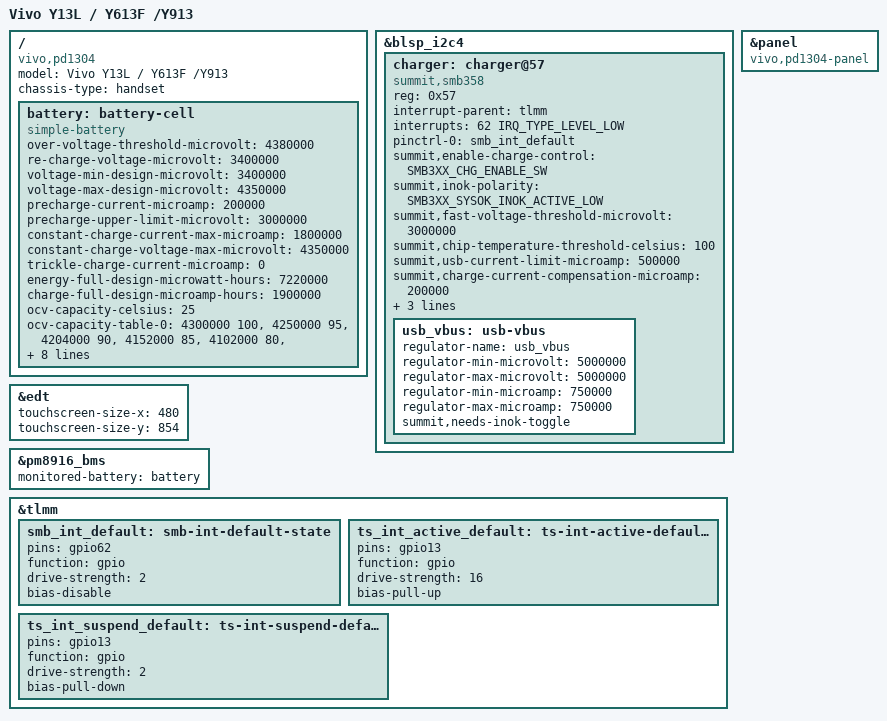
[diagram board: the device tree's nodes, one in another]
// SPDX-License-Identifier: GPL-2.0-only

/dts-v1/;

#include "msm8916-vivo-cdp.dtsi"



/ {
	model = "Vivo Y13L / Y613F /Y913";
	compatible = "vivo,pd1304", "qcom,msm8916";
	chassis-type = "handset";
	
	battery: battery-cell {
		compatible = "simple-battery";
		over-voltage-threshold-microvolt = <4380000>;
		re-charge-voltage-microvolt = <3400000>;
		voltage-min-design-microvolt = <3400000>;
		voltage-max-design-microvolt = <4350000>;

		precharge-current-microamp = <200000>;
		precharge-upper-limit-microvolt = <3000000>;
		constant-charge-current-max-microamp = <1800000>;
		constant-charge-voltage-max-microvolt = <4350000>;
		trickle-charge-current-microamp = <0>;

		energy-full-design-microwatt-hours = <7220000>;
		charge-full-design-microamp-hours = <1900000>;

		ocv-capacity-celsius = <25>;
		ocv-capacity-table-0 = <4300000 100>, <4250000 95>, <4204000 90>,
			<4152000 85>, <4102000 80>, <4060000 75>, <3998000 70>,
			<3964000 65>, <3924000 60>, <3874000 55>, <3842000 50>,
			<3820000 45>, <3800000 40>, <3785000 35>, <3765000 30>,
			<3758000 25>, <3735000 20>, <3706000 16>, <3690000 13>,
			<3687000 11>, <3686000 10>, <3684000 9>, <3680000 8>,
			<3668000 7>, <3640000 6>, <3596000 5>, <3542000 4>,
			<3472000 3>, <3378000 2>, <3239000 1>, <3000000 0>;
	};
	

};

&blsp_i2c4 {
	status = "okay";

	charger: charger@57 {
		compatible = "summit,smb358";
		reg = <0x57>;

		interrupt-parent = <&tlmm>;
		interrupts = <62 IRQ_TYPE_LEVEL_LOW>;

		pinctrl-names = "default";
		pinctrl-0 = <&smb_int_default>;

		summit,enable-charge-control = <SMB3XX_CHG_ENABLE_SW>;
		summit,inok-polarity = <SMB3XX_SYSOK_INOK_ACTIVE_LOW>;
		summit,fast-voltage-threshold-microvolt = <3000000>;
		summit,chip-temperature-threshold-celsius = <100>;
		summit,usb-current-limit-microamp = <500000>;
		summit,charge-current-compensation-microamp = <200000>;
		summit,enable-usb-charging;
		summit,enable-otg-charging;

		monitored-battery = <&battery>;

		usb_vbus: usb-vbus {
			regulator-name = "usb_vbus";
			regulator-min-microvolt = <5000000>;
			regulator-max-microvolt = <5000000>;
			regulator-min-microamp = <750000>;
			regulator-max-microamp = <750000>;
			summit,needs-inok-toggle;
		};
	};
};

&edt{
	touchscreen-size-x = <480>;
	touchscreen-size-y = <854>;

};

&pm8916_bms {
	monitored-battery = <&battery>;
	status = "okay";
};


&panel {
    compatible = "vivo,pd1304-panel"; 


};

&tlmm{

    smb_int_default: smb-int-default-state {
		pins = "gpio62";
		function = "gpio";

		drive-strength = <2>;
		bias-disable;
	};
	
	ts_int_active_default: ts-int-active-default-state {
		pins = "gpio13";
		function = "gpio";
		drive-strength = <16>;
		bias-pull-up;
	};

	ts_int_suspend_default: ts-int-suspend-default-state {
		pins = "gpio13";
		function = "gpio";
		drive-strength = <2>;
		bias-pull-down;
	};


};
